# HDSC_HC32L157KX register map
Vendor: HDSC Co.Ltd; Series: ARMCM0P; File version: 1.2
CPU: CM0 r0p0, little endian, no MPU, no FPU, 3 interrupt priority bits
Registers are 8-bit, read-write, reset 0x0 unless marked. A register's access mark holds for its fields unless they carry their own. Offsets are from the block's base; [hi:lo] are bit positions; {n}, {i} and the like mark numbered series.

## GPIO
Base 0x40033000
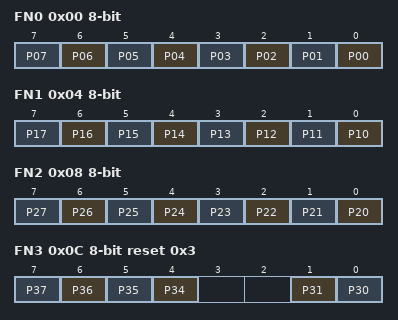
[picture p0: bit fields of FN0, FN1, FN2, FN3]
0x00 FN0
  [n] P{n:02} (n=0..7)
0x04 FN1
  [n-10] P{n} (n=10..17)
0x08 FN2
  [n-20] P{n} (n=20..27)
0x0C FN3 reset 0x3
  [n-30] P{n} (n=34..37), [1] P31, [0] P30
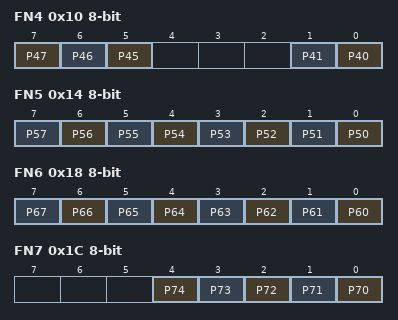
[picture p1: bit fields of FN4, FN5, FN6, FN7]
0x10 FN4
  [7] P47, [6] P46, [5] P45, [1] P41, [0] P40
0x14 FN5
  [n-50] P{n} (n=50..57)
0x18 FN6
  [n-60] P{n} (n=60..67)
0x1C FN7
  [n-70] P{n} (n=70..74)
0x20 FN8
  [0] P80
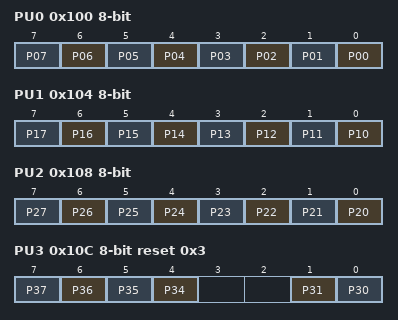
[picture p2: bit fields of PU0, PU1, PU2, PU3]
0x100 PU0
  [n] P{n:02} (n=0..7)
0x104 PU1
  [n-10] P{n} (n=10..17)
0x108 PU2
  [n-20] P{n} (n=20..27)
0x10C PU3 reset 0x3
  [n-30] P{n} (n=34..37), [1] P31, [0] P30
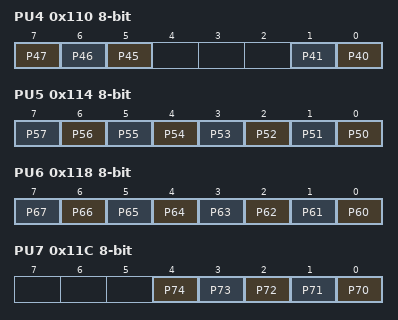
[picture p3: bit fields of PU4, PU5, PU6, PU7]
0x110 PU4
  [7] P47, [6] P46, [5] P45, [1] P41, [0] P40
0x114 PU5
  [n-50] P{n} (n=50..57)
0x118 PU6
  [n-60] P{n} (n=60..67)
0x11C PU7
  [n-70] P{n} (n=70..74)
0x120 PU8
  [0] P80
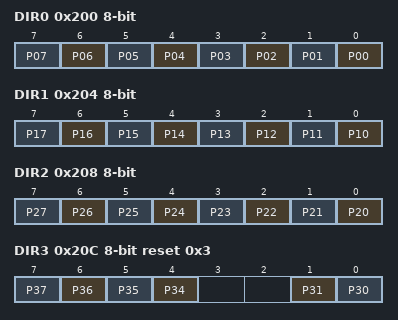
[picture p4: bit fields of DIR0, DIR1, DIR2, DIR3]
0x200 DIR0
  [n] P{n:02} (n=0..7)
0x204 DIR1
  [n-10] P{n} (n=10..17)
0x208 DIR2
  [n-20] P{n} (n=20..27)
0x20C DIR3 reset 0x3
  [n-30] P{n} (n=34..37), [1] P31, [0] P30
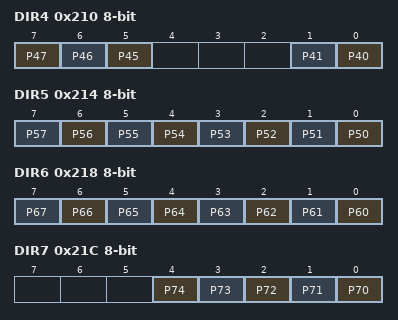
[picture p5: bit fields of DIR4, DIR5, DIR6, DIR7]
0x210 DIR4
  [7] P47, [6] P46, [5] P45, [1] P41, [0] P40
0x214 DIR5
  [n-50] P{n} (n=50..57)
0x218 DIR6
  [n-60] P{n} (n=60..67)
0x21C DIR7
  [n-70] P{n} (n=70..74)
0x220 DIR8
  [0] P80
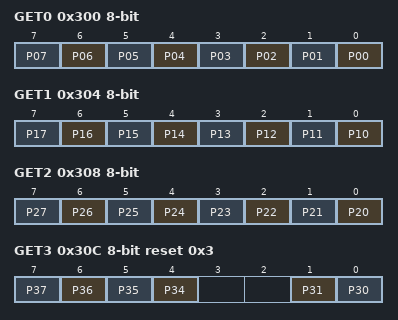
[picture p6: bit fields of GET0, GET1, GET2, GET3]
0x300 GET0
  [n] P{n:02} (n=0..7)
0x304 GET1
  [n-10] P{n} (n=10..17)
0x308 GET2
  [n-20] P{n} (n=20..27)
0x30C GET3 reset 0x3
  [n-30] P{n} (n=34..37), [1] P31, [0] P30
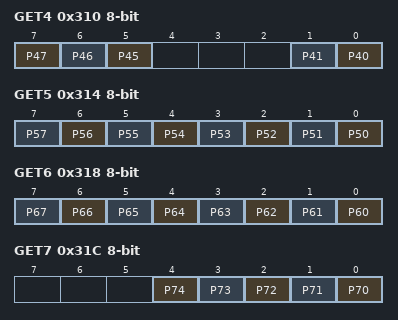
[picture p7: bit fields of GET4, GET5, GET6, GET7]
0x310 GET4
  [7] P47, [6] P46, [5] P45, [1] P41, [0] P40
0x314 GET5
  [n-50] P{n} (n=50..57)
0x318 GET6
  [n-60] P{n} (n=60..67)
0x31C GET7
  [n-70] P{n} (n=70..74)
0x320 GET8
  [0] P80
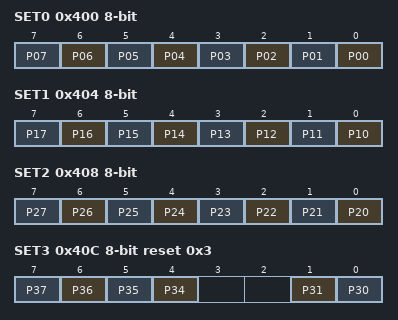
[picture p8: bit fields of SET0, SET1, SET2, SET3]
0x400 SET0
  [n] P{n:02} (n=0..7)
0x404 SET1
  [n-10] P{n} (n=10..17)
0x408 SET2
  [n-20] P{n} (n=20..27)
0x40C SET3 reset 0x3
  [n-30] P{n} (n=34..37), [1] P31, [0] P30
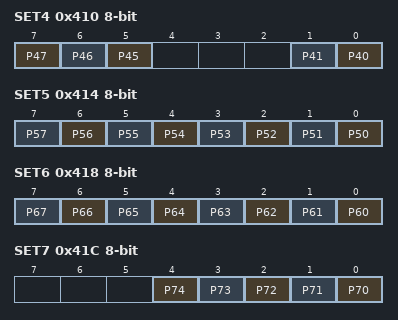
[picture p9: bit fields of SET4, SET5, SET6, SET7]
0x410 SET4
  [7] P47, [6] P46, [5] P45, [1] P41, [0] P40
0x414 SET5
  [n-50] P{n} (n=50..57)
0x418 SET6
  [n-60] P{n} (n=60..67)
0x41C SET7
  [n-70] P{n} (n=70..74)
0x420 SET8
  [0] P80
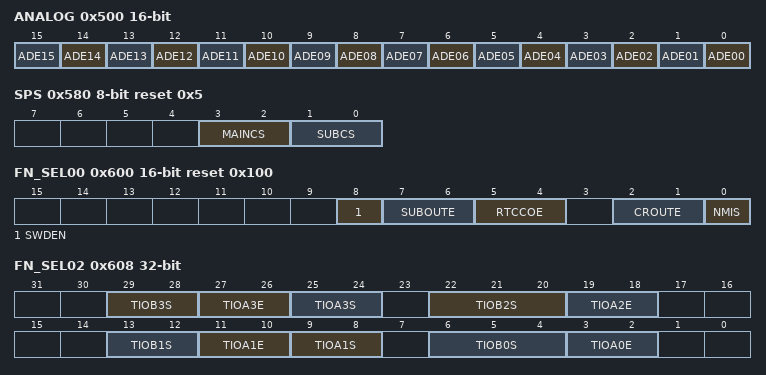
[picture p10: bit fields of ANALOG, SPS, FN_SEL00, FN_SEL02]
0x500 ANALOG 16-bit
  [n] ADE{n:02} (n=0..15)
0x580 SPS reset 0x5
  [3:2] MAINCS, [1:0] SUBCS
0x600 FN_SEL00 16-bit reset 0x100
  [8] SWDEN, [7:6] SUBOUTE, [5:4] RTCCOE, [2:1] CROUTE, [0] NMIS
0x608 FN_SEL02 32-bit
  [29:28] TIOB3S, [8n+3:8n+2] TIOA{n}E (n=0..3), [25:24] TIOA3S, [22:20] TIOB2S, [13:12] TIOB1S, [9:8] TIOA1S, [6:4] TIOB0S
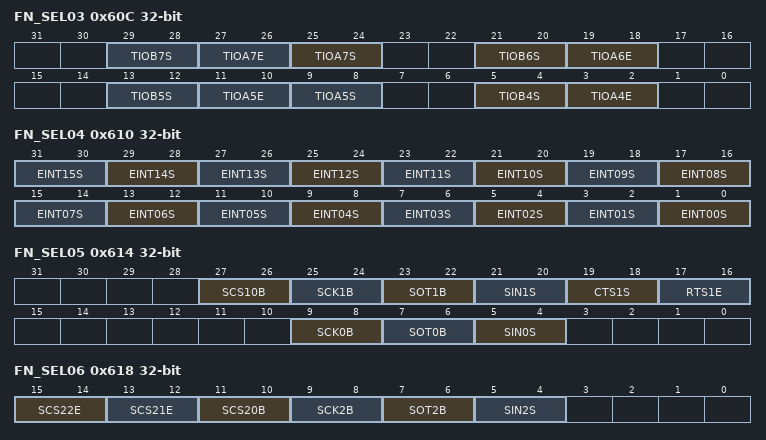
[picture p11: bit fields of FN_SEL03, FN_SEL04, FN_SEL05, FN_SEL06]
0x60C FN_SEL03 32-bit
  [8n-27:8n-28] TIOB{n}S (n=4..7), [8n-29:8n-30] TIOA{n}E (n=4..7), [25:24] TIOA7S, [9:8] TIOA5S
0x610 FN_SEL04 32-bit
  [2n+1:2n] EINT{n:02}S (n=0..15)
0x614 FN_SEL05 32-bit
  [27:26] SCS10B, [25:24] SCK1B, [23:22] SOT1B, [21:20] SIN1S, [19:18] CTS1S, [17:16] RTS1E, [9:8] SCK0B, [7:6] SOT0B, [5:4] SIN0S
0x618 FN_SEL06 32-bit
  [15:14] SCS22E, [13:12] SCS21E, [11:10] SCS20B, [9:8] SCK2B, [7:6] SOT2B, [5:4] SIN2S
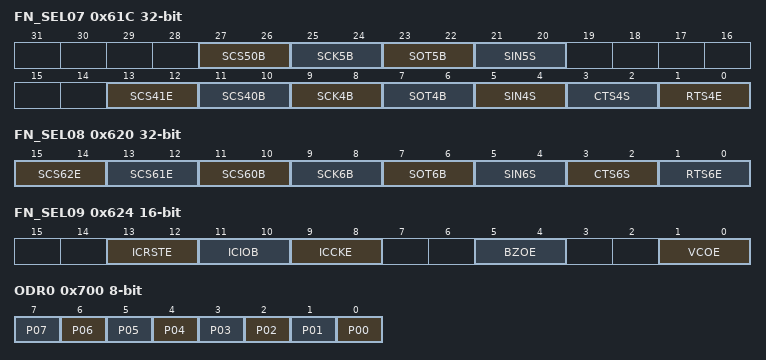
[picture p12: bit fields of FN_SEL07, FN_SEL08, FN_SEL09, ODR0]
0x61C FN_SEL07 32-bit
  [27:26] SCS50B, [25:24] SCK5B, [23:22] SOT5B, [21:20] SIN5S, [13:12] SCS41E, [11:10] SCS40B, [9:8] SCK4B, [7:6] SOT4B, [5:4] SIN4S, [3:2] CTS4S, [1:0] RTS4E
0x620 FN_SEL08 32-bit
  [15:14] SCS62E, [13:12] SCS61E, [11:10] SCS60B, [9:8] SCK6B, [7:6] SOT6B, [5:4] SIN6S, [3:2] CTS6S, [1:0] RTS6E
0x624 FN_SEL09 16-bit
  [13:12] ICRSTE, [11:10] ICIOB, [9:8] ICCKE, [5:4] BZOE, [1:0] VCOE
0x700 ODR0
  [n] P{n:02} (n=0..7)
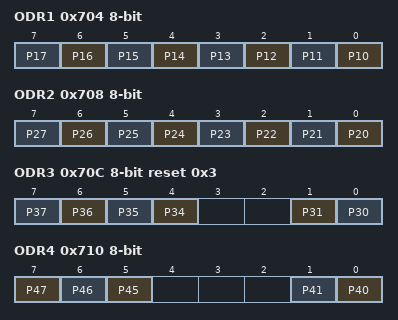
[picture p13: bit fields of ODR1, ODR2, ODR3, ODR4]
0x704 ODR1
  [n-10] P{n} (n=10..17)
0x708 ODR2
  [n-20] P{n} (n=20..27)
0x70C ODR3 reset 0x3
  [n-30] P{n} (n=34..37), [1] P31, [0] P30
0x710 ODR4
  [7] P47, [6] P46, [5] P45, [1] P41, [0] P40
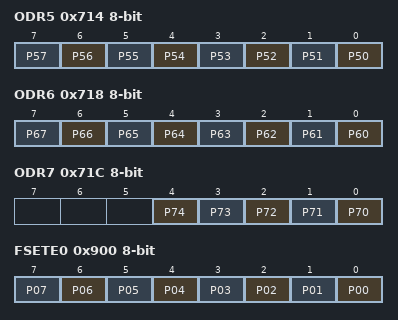
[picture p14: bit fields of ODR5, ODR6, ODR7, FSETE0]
0x714 ODR5
  [n-50] P{n} (n=50..57)
0x718 ODR6
  [n-60] P{n} (n=60..67)
0x71C ODR7
  [n-70] P{n} (n=70..74)
0x720 ODR8
  [0] P80
0x740 LVDIE
  [0] LVDIE
0x900 FSETE0
  [n] P{n:02} (n=0..7)
0x904 FSETE1
  [n-10] P{n} (n=10..17)
0x908 FSETE2
  [n-20] P{n} (n=20..27)
0x90C FSETE3 reset 0x3
  [n-30] P{n} (n=34..37), [1] P31, [0] P30
0x910 FSETE4
  [7] P47, [6] P46, [5] P45, [1] P41, [0] P40
0x914 FSETE5
  [n-50] P{n} (n=50..57)
0x918 FSETE6
  [n-60] P{n} (n=60..67)
0x91C FSETE7
  [n-70] P{n} (n=70..74)
0x920 FSETE8
  [0] P80
